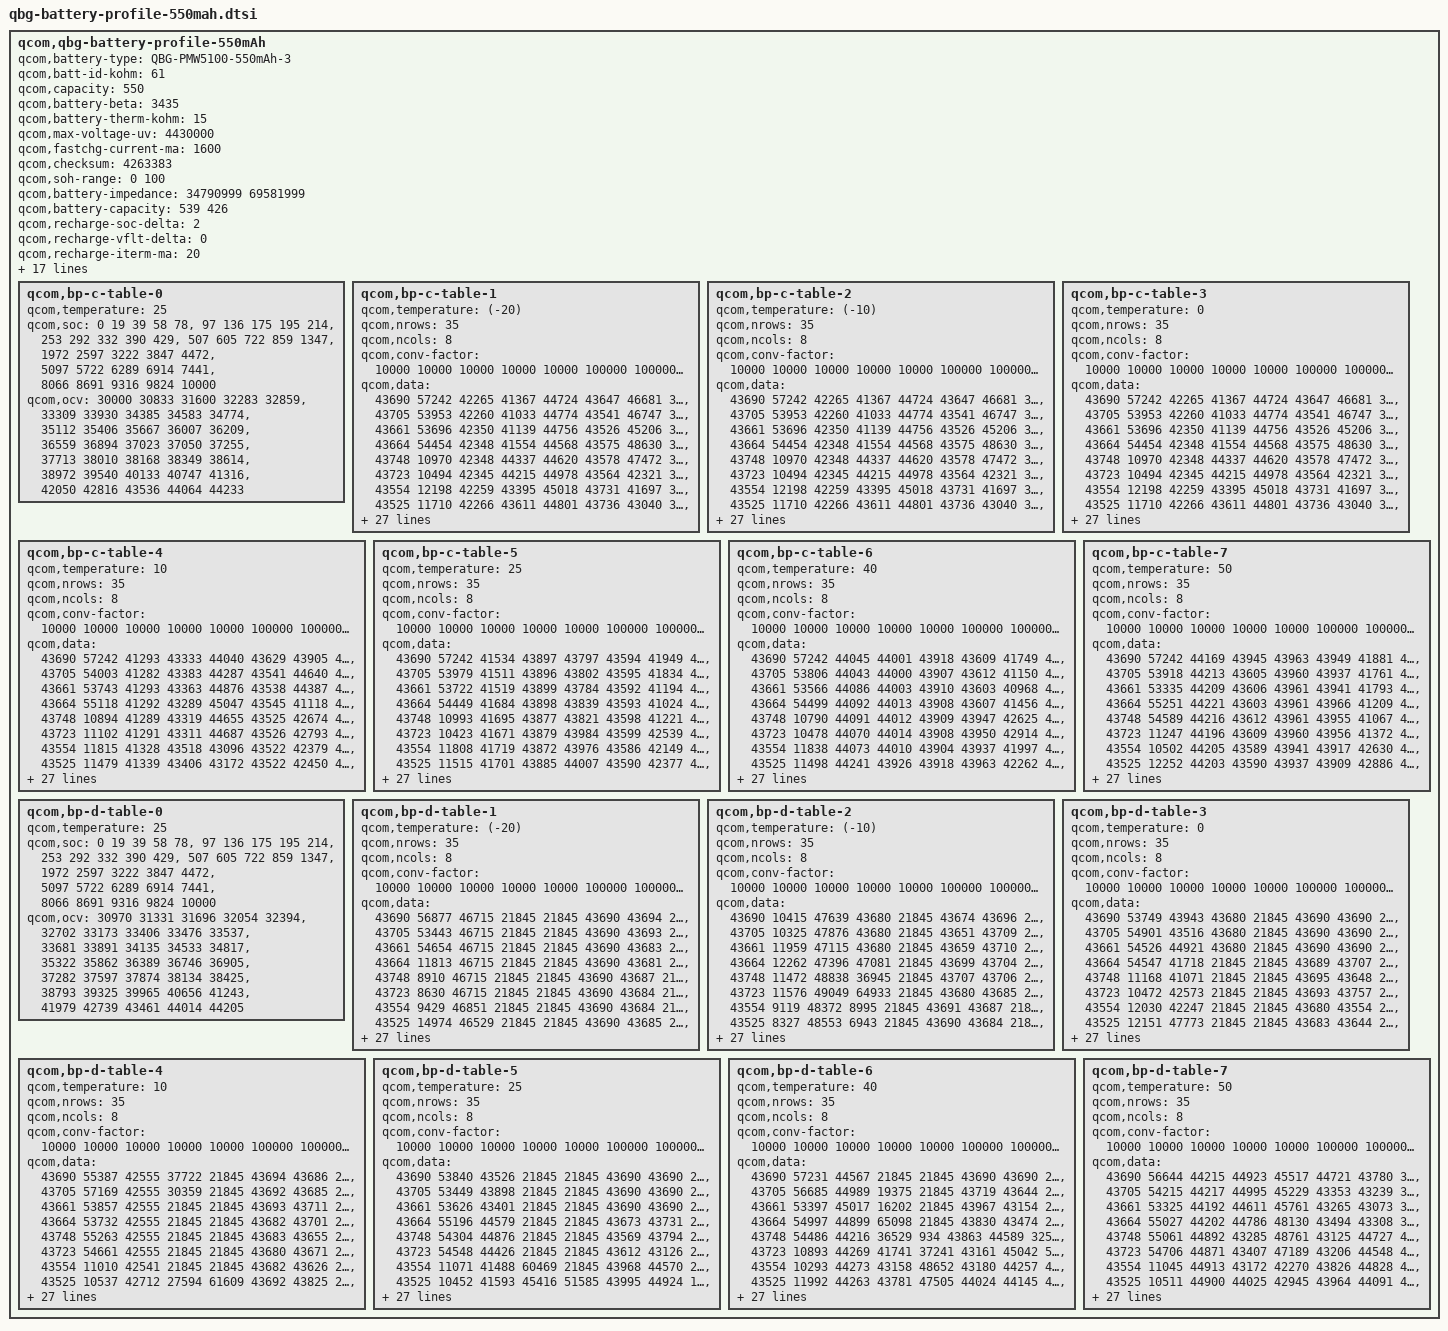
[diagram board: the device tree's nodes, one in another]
qcom,qbg-battery-profile-550mAh {
	qcom,battery-type = "QBG-PMW5100-550mAh-3";
	qcom,batt-id-kohm = <61>;
	qcom,capacity = <550>;
	qcom,battery-beta = <3435>;
	qcom,battery-therm-kohm = <15>;
	qcom,max-voltage-uv = <4430000>;
	qcom,fastchg-current-ma = <1600>;
	qcom,checksum = <4263383>; /*@5, 0.005V, 6.0% */
	qcom,soh-range = <0 100>;
	/* Nominal_Impedance in 10nohm @ SOC 50% 25C* 0:fresh cell,  1: aged cell */
	qcom,battery-impedance = <34790999 69581999>;
	/* Nominal_Capacity in mAh. 0: fresh cell,  1:aged cell */
	qcom,battery-capacity = <539 426>;
	/* SOC delta (in percent) dropped from EOC SOC to enable recharge */
	qcom,recharge-soc-delta =<2>;
	/* vfloat delta (in mV) dropped from regular vfloat in recharge */
	qcom,recharge-vflt-delta =<0>;
	/* Termination current (in mA) in recharge */
	qcom,recharge-iterm-ma = <20>;
	qcom,batt-temp-coeffs =    <0 70 120 170 425 440 530>;
	qcom,batt-current-coeffs = <0 250000 525000 800000 1600000 650000 300000>;
	qcom,batt-max-mv-coeffs = <4130000 4430000>;
	qcom,chg-limit-current-default = <150000>;

	qcom,jeita-fcc-ranges = <0  70  250000
                            	71 440 1600000
                            	441 530 300000>;

   	 qcom,jeita-fv-ranges = <0  70  4430000
                           	71  440 4430000
                           	441 530 4130000>;

	qcom,step-chg-ranges = <3400000  4250000  1600000
				4250001  4350000  1250000
				4350001  4430000  1100000>;
    	/* COOL = 15 DegC, WARM = 70 DegC */
    	qcom,jeita-soft-thresholds = <0x30DD 0x7BC>;
    	/* COLD = 0 DegC, HOT = 80 DegC */
    	qcom,jeita-hard-thresholds = <0x3733 0x5ed>;
   	/* COOL = 18 DegC, WARM = 39 DegC*/
    	qcom,jeita-soft-hys-thresholds = <0x256e 0x161b>;
    	qcom,jeita-soft-fcc-ua = <250000 650000>;
    	qcom,jeita-soft-fv-uv = <4430000 4430000>;

	qcom,bp-c-table-0 {
		qcom,temperature = <25>;
		qcom,soc = <    0    19    39    58    78>,
			<   97   136   175   195   214>,
			<  253   292   332   390   429>,
			<  507   605   722   859  1347>,
			< 1972  2597  3222  3847  4472>,
			< 5097  5722  6289  6914  7441>,
			< 8066  8691  9316  9824 10000>;
		qcom,ocv = <30000 30833 31600 32283 32859>,
			<33309 33930 34385 34583 34774>,
			<35112 35406 35667 36007 36209>,
			<36559 36894 37023 37050 37255>,
			<37713 38010 38168 38349 38614>,
			<38972 39540 40133 40747 41316>,
			<42050 42816 43536 44064 44233>;
	};

	qcom,bp-c-table-1 {
		qcom,temperature = <(-20)>;
		qcom,nrows = <35>;
		qcom,ncols = <8>;
		qcom,conv-factor = <10000 10000 10000 10000 10000 100000 100000 10000>;
		qcom,data = <43690 57242 42265 41367 44724 43647 46681 39662>,
			    <43705 53953 42260 41033 44774 43541 46747 34189>,
			    <43661 53696 42350 41139 44756 43526 45206 34681>,
			    <43664 54454 42348 41554 44568 43575 48630 34557>,
			    <43748 10970 42348 44337 44620 43578 47472 32879>,
			    <43723 10494 42345 44215 44978 43564 42321 33671>,
			    <43554 12198 42259 43395 45018 43731 41697 35968>,
			    <43525 11710 42266 43611 44801 43736 43040 35192>,
			    <43625 11590 42244 43765 44819 43739 43964 35236>,
			    <43644  8731 42247 43754 44816 43736 43646 34869>,
			    <43607  8361 42252 43677 44808 43735 43647 35001>,
			    <43918  8628 42292 43672 44844 43559 43645 35612>,
			    <44006  9911 42291 43674 44841 43577 43639 35780>,
			    <43820 10176 42282 43672 44847 43582 43591 35767>,
			    <43783  9370 42462 43673 44846 43582 43611 35400>,
			    <43857  9507 42465 43675 44998 43571 43609 35531>,
			    <43255 14852 42396 43692 44948 43073 43594 46348>,
			    <43128 14929 42393 43748 45028 43581 43613 46534>,
			    <43505 15283 42392 43235 43289 43535 45030 46363>,
			    <45033 15191 42413 44648 43325 43540 41374 35436>,
			    <44318 14666 42082 44982 45042 43616 41414 35824>,
			    <41103 16310 41998 45012 44281 43623 41333 35589>,
			    <42556 16178 42043 44806 44091 43617 42660 35620>,
			    <42413 15505 42025 44916 44254 43628 41312 35729>,
			    <48082 15795 42030 44169 44285 43625 40979 35752>,
			    <47427 13026 42138 44918 44435 43627 44394 35821>,
			    <48368 13174 42165 44269 44374 43626 42807 35002>,
			    <45627 13873 42161 44820 44619 43543 41661 46218>,
			    <45480 13412 42145 44871 44636 43543 41150 46329>,
			    <47035  2643 42823 44876 44575 43536 41635 46252>,
			    <46376  2308 42847 44168 44939 43537 44334 46507>,
			    <35673  3129 42823 44061 44171 43548 44128 35817>,
			    <36558   991 42211 44244 41083 43630 44604 33291>,
			    <36042   262 42108 43439 42075 43253 43860 34711>,
			    <36282  1767 42443 43898 42551 43535 44018 33279>;
	};

	qcom,bp-c-table-2 {
		qcom,temperature = <(-10)>;
		qcom,nrows = <35>;
		qcom,ncols = <8>;
		qcom,conv-factor = <10000 10000 10000 10000 10000 100000 100000 10000>;
		qcom,data = <43690 57242 42265 41367 44724 43647 46681 39662>,
			    <43705 53953 42260 41033 44774 43541 46747 34189>,
			    <43661 53696 42350 41139 44756 43526 45206 34681>,
			    <43664 54454 42348 41554 44568 43575 48630 34557>,
			    <43748 10970 42348 44337 44620 43578 47472 32879>,
			    <43723 10494 42345 44215 44978 43564 42321 33671>,
			    <43554 12198 42259 43395 45018 43731 41697 35968>,
			    <43525 11710 42266 43611 44801 43736 43040 35192>,
			    <43625 11590 42244 43765 44819 43739 43964 35236>,
			    <43644  8731 42247 43754 44816 43736 43646 34869>,
			    <43607  8361 42252 43677 44808 43735 43647 35001>,
			    <43918  8628 42292 43672 44844 43559 43645 35612>,
			    <44006  9911 42291 43674 44841 43577 43639 35780>,
			    <43820 10176 42282 43672 44847 43582 43591 35767>,
			    <43783  9370 42462 43673 44846 43582 43611 35400>,
			    <43857  9507 42465 43675 44998 43571 43609 35531>,
			    <43255 14852 42396 43692 44948 43073 43594 46348>,
			    <43128 14929 42393 43748 45028 43581 43613 46534>,
			    <43505 15283 42392 43235 43289 43535 45030 46363>,
			    <45033 15191 42413 44648 43325 43540 41374 35436>,
			    <44318 14666 42082 44982 45042 43616 41414 35824>,
			    <41103 16310 41998 45012 44281 43623 41333 35589>,
			    <42556 16178 42043 44806 44091 43617 42660 35620>,
			    <42413 15505 42025 44916 44254 43628 41312 35729>,
			    <48082 15795 42030 44169 44285 43625 40979 35752>,
			    <47427 13026 42138 44918 44435 43627 44394 35821>,
			    <48368 13174 42165 44269 44374 43626 42807 35002>,
			    <45627 13873 42161 44820 44619 43543 41661 46218>,
			    <45480 13412 42145 44871 44636 43543 41150 46329>,
			    <47035  2643 42823 44876 44575 43536 41635 46252>,
			    <46376  2308 42847 44168 44939 43537 44334 46507>,
			    <35673  3129 42823 44061 44171 43548 44128 35817>,
			    <36558   991 42211 44244 41083 43630 44604 33291>,
			    <36042   262 42108 43439 42075 43253 43860 34711>,
			    <36282  1767 42443 43898 42551 43535 44018 33279>;
	};

	qcom,bp-c-table-3 {
		qcom,temperature = <0>;
		qcom,nrows = <35>;
		qcom,ncols = <8>;
		qcom,conv-factor = <10000 10000 10000 10000 10000 100000 100000 10000>;
		qcom,data = <43690 57242 42265 41367 44724 43647 46681 39662>,
			    <43705 53953 42260 41033 44774 43541 46747 34189>,
			    <43661 53696 42350 41139 44756 43526 45206 34681>,
			    <43664 54454 42348 41554 44568 43575 48630 34557>,
			    <43748 10970 42348 44337 44620 43578 47472 32879>,
			    <43723 10494 42345 44215 44978 43564 42321 33671>,
			    <43554 12198 42259 43395 45018 43731 41697 35968>,
			    <43525 11710 42266 43611 44801 43736 43040 35192>,
			    <43625 11590 42244 43765 44819 43739 43964 35236>,
			    <43644  8731 42247 43754 44816 43736 43646 34869>,
			    <43607  8361 42252 43677 44808 43735 43647 35001>,
			    <43918  8628 42292 43672 44844 43559 43645 35612>,
			    <44006  9911 42291 43674 44841 43577 43639 35780>,
			    <43820 10176 42282 43672 44847 43582 43591 35767>,
			    <43783  9370 42462 43673 44846 43582 43611 35400>,
			    <43857  9507 42465 43675 44998 43571 43609 35531>,
			    <43255 14852 42396 43692 44948 43073 43594 46348>,
			    <43128 14929 42393 43748 45028 43581 43613 46534>,
			    <43505 15283 42392 43235 43289 43535 45030 46363>,
			    <45033 15191 42413 44648 43325 43540 41374 35436>,
			    <44318 14666 42082 44982 45042 43616 41414 35824>,
			    <41103 16310 41998 45012 44281 43623 41333 35589>,
			    <42556 16178 42043 44806 44091 43617 42660 35620>,
			    <42413 15505 42025 44916 44254 43628 41312 35729>,
			    <48082 15795 42030 44169 44285 43625 40979 35752>,
			    <47427 13026 42138 44918 44435 43627 44394 35821>,
			    <48368 13174 42165 44269 44374 43626 42807 35002>,
			    <45627 13873 42161 44820 44619 43543 41661 46218>,
			    <45480 13412 42145 44871 44636 43543 41150 46329>,
			    <47035  2643 42823 44876 44575 43536 41635 46252>,
			    <46376  2308 42847 44168 44939 43537 44334 46507>,
			    <35673  3129 42823 44061 44171 43548 44128 35817>,
			    <36558   991 42211 44244 41083 43630 44604 33291>,
			    <36042   262 42108 43439 42075 43253 43860 34711>,
			    <36282  1767 42443 43898 42551 43535 44018 33279>;
	};

	qcom,bp-c-table-4 {
		qcom,temperature = <10>;
		qcom,nrows = <35>;
		qcom,ncols = <8>;
		qcom,conv-factor = <10000 10000 10000 10000 10000 100000 100000 10000>;
		qcom,data = <43690 57242 41293 43333 44040 43629 43905 46094>,
			    <43705 54003 41282 43383 44287 43541 44640 46971>,
			    <43661 53743 41293 43363 44876 43538 44387 46656>,
			    <43664 55118 41292 43289 45047 43545 41118 45395>,
			    <43748 10894 41289 43319 44655 43525 42674 45481>,
			    <43723 11102 41291 43311 44687 43526 42793 45242>,
			    <43554 11815 41328 43518 43096 43522 42379 45798>,
			    <43525 11479 41339 43406 43172 43522 42450 48207>,
			    <43625 11768 41319 43431 43877 43522 42464 48335>,
			    <43644  8883 41314 43100 43807 43523 42006 48291>,
			    <43607  9170 41238 43030 43835 43546 41443 49116>,
			    <43918  8206 41220 43065 43990 43539 41610 49082>,
			    <44006  8455 41268 43045 43995 43541 44370 48760>,
			    <43820 10155 41256 43045 43970 43631 41727 48700>,
			    <43783 10080 41415 43040 43969 43618 41701 48860>,
			    <43857  9614 41440 43225 43818 43617 44329 48789>,
			    <43255 15092 41423 43231 43983 43617 41580 47448>,
			    <43128 14873 41414 43047 44004 43622 41199 47388>,
			    <43505 14969 41441 43061 43996 43622 41018 47381>,
			    <45033 15108 41449 43094 43113 43638 41090 48741>,
			    <44318 14636 41386 43496 44715 43587 41397 48945>,
			    <41103 15894 41039 43314 44640 43599 41245 48275>,
			    <42556 16277 41087 43288 44608 43596 42656 48311>,
			    <42413 16196 40982 43388 44557 43594 41221 48925>,
			    <48082 15433 40973 44705 44753 43635 41203 48940>,
			    <47427 12956 40999 44700 44646 43646 44303 48997>,
			    <48368 12435 41154 43269 44855 43645 44114 49011>,
			    <45627 13938 41197 43312 43447 43600 44292 47522>,
			    <45480 13747 41114 43370 43408 43601 44364 47519>,
			    <47035  3048 41095 43390 43508 43641 44309 47604>,
			    <46376  3770 41141 43331 43286 43641 44145 47445>,
			    <35673  3499 41103 44684 44776 43645 44147 49077>,
			    <36558   886 41205 44775 44151 43644 45010 45692>,
			    <36042   320 41387 43474 41893 43591 43515 45433>,
			    <36282  1598 41422 43104 41658 43941 43237 45465>;
	};

	qcom,bp-c-table-5 {
		qcom,temperature = <25>;
		qcom,nrows = <35>;
		qcom,ncols = <8>;
		qcom,conv-factor = <10000 10000 10000 10000 10000 100000 100000 10000>;
		qcom,data = <43690 57242 41534 43897 43797 43594 41949 42819>,
			    <43705 53979 41511 43896 43802 43595 41834 42863>,
			    <43661 53722 41519 43899 43784 43592 41194 42760>,
			    <43664 54449 41684 43898 43839 43593 41024 42794>,
			    <43748 10993 41695 43877 43821 43598 41221 42997>,
			    <43723 10423 41671 43879 43984 43599 42539 42901>,
			    <43554 11808 41719 43872 43976 43586 42149 42921>,
			    <43525 11515 41701 43885 44007 43590 42377 42597>,
			    <43625 11709 41699 43884 44014 43588 42480 42514>,
			    <43644 11644 41705 43887 43921 43589 42484 42505>,
			    <43607  9090 41628 43880 43907 43614 42489 42706>,
			    <43918  8420 41607 43882 43957 43602 42476 42742>,
			    <44006  8697 41603 43796 43912 43606 42493 42750>,
			    <43820  9741 41615 43792 43910 43946 42299 42727>,
			    <43783 10203 41608 43795 43908 43947 42298 42729>,
			    <43857  9317 41660 43800 43930 43945 42445 42636>,
			    <43255 15028 41642 43838 43910 43948 42964 41281>,
			    <43128 14901 44369 43981 43959 43936 42536 41269>,
			    <43505 14864 44359 43985 44026 43937 42497 41343>,
			    <45033 15149 44415 43803 43235 43937 41522 42616>,
			    <44318 14843 44311 43902 43093 43915 41124 42963>,
			    <41103 16080 44296 43860 43505 43966 41344 42865>,
			    <42556 16306 44329 43180 43453 43936 41272 42968>,
			    <42413 16231 44486 43166 43078 43950 40962 42995>,
			    <48082 15484 44513 43257 43081 43602 41614 42977>,
			    <47427 12950 44420 43205 43498 43606 44228 42761>,
			    <48368 12510 44451 43191 43097 43604 44124 42574>,
			    <45627 13935 44102 43891 43864 43609 44501 41410>,
			    <45480 13697 44159 43876 43858 43609 44232 41441>,
			    <47035  3022 44139 43857 43196 43610 44114 41256>,
			    <46376  3816 44057 43193 43213 43589 44254 41294>,
			    <35673  3562 44061 43140 43125 43615 44216 42531>,
			    <36558   186 44135 43070 43385 43950 44202 42169>,
			    <36042  1674 44520 43864 44234 43609 43331 47829>,
			    <36282  1635 44404 44029 44660 43911 43231 42416>;
	};

	qcom,bp-c-table-6 {
		qcom,temperature = <40>;
		qcom,nrows = <35>;
		qcom,ncols = <8>;
		qcom,conv-factor = <10000 10000 10000 10000 10000 100000 100000 10000>;
		qcom,data =<43690 57242 44045 44001 43918 43609 41749 41752>,
			    <43705 53806 44043 44000 43907 43612 41150 41729>,
			    <43661 53566 44086 44003 43910 43603 40968 41742>,
			    <43664 54499 44092 44013 43908 43607 41456 41783>,
			    <43748 10790 44091 44012 43909 43947 42625 41790>,
			    <43723 10478 44070 44014 43908 43950 42914 41766>,
			    <43554 11838 44073 44010 43904 43937 41997 41939>,
			    <43525 11498 44241 43926 43918 43963 42262 41934>,
			    <43625 11348 44253 43920 43914 43960 42311 41971>,
			    <43644 11548 44254 43933 43953 43961 42307 41959>,
			    <43607  8788 44229 43931 43942 43966 42351 41882>,
			    <43918  8375 44224 43911 43947 43964 42243 41904>,
			    <44006  8631 44239 43904 43605 43955 42253 41893>,
			    <43820  9926 44276 43917 43607 43912 42252 41902>,
			    <43783 10136 44273 43916 43601 43916 42244 41559>,
			    <43857  9251 44287 43919 43613 43911 42365 41541>,
			    <43255  9595 44283 43955 43610 43935 42392 41594>,
			    <43128 15050 44259 43595 43637 44027 42590 41685>,
			    <43505 15057 44271 43591 43945 44007 41049 41476>,
			    <45033 15259 44183 43909 43991 44015 41186 41934>,
			    <44318 14426 44186 43935 43889 44001 41068 41747>,
			    <41103 16050 44174 43930 43171 44015 41104 41842>,
			    <42556 15990 44196 43911 43780 43928 41450 41935>,
			    <42413 16128 44880 44012 43791 43956 41587 41923>,
			    <48082 15469 44872 44020 43902 43952 44156 41743>,
			    <47427 13036 44900 43984 43172 43965 44866 41792>,
			    <48368 12336 44818 43911 43829 43908 44231 41915>,
			    <45627 13949 44809 43961 43961 43909 41506 41696>,
			    <45480 13806 44839 43954 43911 43907 44318 41727>,
			    <47035  2860 45014 43927 44029 43912 41519 41522>,
			    <46376  3779 45018 44006 43784 43913 44304 41549>,
			    <35673  3530 45004 43969 43869 43959 44350 41981>,
			    <36558   143 44992 43810 43258 43955 44330 41849>,
			    <36042  1665 44813 44022 44776 43919 45046 41341>,
			    <36282  1651 44271 43914 43466 44030 43322 41469>;
	};

	qcom,bp-c-table-7 {
		qcom,temperature = <50>;
		qcom,nrows = <35>;
		qcom,ncols = <8>;
		qcom,conv-factor = <10000 10000 10000 10000 10000 100000 100000 10000>;
		qcom,data = <43690 57242 44169 43945 43963 43949 41881 41492>,
			    <43705 53918 44213 43605 43960 43937 41761 41503>,
			    <43661 53335 44209 43606 43961 43941 41793 41478>,
			    <43664 55251 44221 43603 43961 43966 41209 41481>,
			    <43748 54589 44216 43612 43961 43955 41067 41520>,
			    <43723 11247 44196 43609 43960 43956 41372 41528>,
			    <43554 10502 44205 43589 43941 43917 42630 41515>,
			    <43525 12252 44203 43590 43937 43909 42886 41688>,
			    <43625 11498 44884 43585 43939 43931 42756 41665>,
			    <43644 11349 44886 43585 43948 43928 42135 41678>,
			    <43607  8955 44882 43584 43605 43934 42284 41714>,
			    <43918  9181 44894 43585 43602 43935 47824 41697>,
			    <44006  8404 44891 43584 43611 43933 48043 41621>,
			    <43820  8572 44870 43586 43586 43926 47929 41604>,
			    <43783  9739 44864 43597 43598 43925 47879 41615>,
			    <43857  9384 44877 43598 43639 44015 47968 41663>,
			    <43255  9718 44875 43637 43641 44005 47286 41642>,
			    <43128 15031 44916 43548 43547 43820 42328 44289>,
			    <43505 14993 44918 43549 43616 43987 41265 44393>,
			    <45033 14960 44914 43945 43905 43982 42767 41688>,
			    <44318 14388 44901 43615 44024 43999 42686 41518>,
			    <41103 14719 44911 43592 43996 43992 41124 41530>,
			    <42556 15893 44818 43637 43910 43976 41362 41628>,
			    <42413 16180 44800 43939 43930 44004 41022 41712>,
			    <48082 15458 44850 43907 44016 44014 41519 41481>,
			    <47427 13048 44834 44009 43985 43934 44324 41592>,
			    <48368 12293 45019 43607 43959 44005 41595 41637>,
			    <45627 13895 45002 43646 43621 44028 41010 44499>,
			    <45480 13813 45028 43633 43608 44019 41972 44345>,
			    <47035  2818 44945 43587 43915 44024 41570 44395>,
			    <46376  3619 44931 43942 44023 44013 41765 41656>,
			    <35673  3543 44982 43954 43786 44010 41520 41724>,
			    <36558   153 44989 43926 43892 44015 41858 41502>,
			    <36042  1692 44949 43938 43453 44014 44908 41803>,
			    <36282  1610 44918 43930 43256 43814 44947 41805>;
	};

	qcom,bp-d-table-0 {
		qcom,temperature = <25>;
		qcom,soc = <    0    19    39    58    78>,
			<   97   136   175   195   214>,
			<  253   292   332   390   429>,
			<  507   605   722   859  1347>,
			< 1972  2597  3222  3847  4472>,
			< 5097  5722  6289  6914  7441>,
			< 8066  8691  9316  9824 10000>;
		qcom,ocv = <30970 31331 31696 32054 32394>,
			<32702 33173 33406 33476 33537>,
			<33681 33891 34135 34533 34817>,
			<35322 35862 36389 36746 36905>,
			<37282 37597 37874 38134 38425>,
			<38793 39325 39965 40656 41243>,
			<41979 42739 43461 44014 44205>;
	};

	qcom,bp-d-table-1 {
		qcom,temperature = <(-20)>;
		qcom,nrows = <35>;
		qcom,ncols = <8>;
		qcom,conv-factor = <10000 10000 10000 10000 10000 100000 100000 10000>;
		qcom,data = <43690 56877 46715 21845 21845 43690 43694 21845>,
			    <43705 53443 46715 21845 21845 43690 43693 21845>,
			    <43661 54654 46715 21845 21845 43690 43683 21845>,
			    <43664 11813 46715 21845 21845 43690 43681 21845>,
			    <43748  8910 46715 21845 21845 43690 43687 21845>,
			    <43723  8630 46715 21845 21845 43690 43684 21845>,
			    <43554  9429 46851 21845 21845 43690 43684 21845>,
			    <43525 14974 46529 21845 21845 43690 43685 21845>,
			    <43625 15345 35499 21845 21845 43690 43685 21845>,
			    <43644 15353 35469 21845 21845 43690 43685 21845>,
			    <43607  9555 35563 21845 21845 43690 43687 21845>,
			    <43918  9253 35567 21845 21845 43690 43687 21845>,
			    <44006  9217 35481 21845 21845 43690 43687 21845>,
			    <43820  9587 46421 21845 21845 43690 43704 21845>,
			    <43783  9584 35467 21845 21845 43691 43729 21845>,
			    <43857  9280 35814 21845 35524 43692 43310 21845>,
			    <43255  9666 46591 21845 46116 43692 43426 21845>,
			    <43128  9582 35457 21845 48573 43692 43275 21845>,
			    <43505  9557 46305 24215 47344 43693 43315 21845>,
			    <45033 14849 46875 16201 42248 43689 43863 21845>,
			    <44318 15204 46917 50923 42126 43688 43259 21686>,
			    <41103 14448 47057 63694 42816 43688 43202 30014>,
			    <42556 14619 47058 38092 42995 43688 43234 27745>,
			    <42413 16068 47051 39588 42509 43688 43246  8163>,
			    <48082 16264 46881 36547 42688 43689 43183  3946>,
			    <47427 16215 47066 46772 42719 43689 43847 12483>,
			    <48368 15836 46870 45795 42771 43694 43061 16073>,
			    <45627 13178 46875 45972 47536 43694 44747 15640>,
			    <45480 14328 46864 46738 46554 43693 44515  3713>,
			    <47035  2801 46675 45246 34706 43683 44548  2023>,
			    <46376  2209 46865 45815 35407 43711 43027  2675>,
			    <35673  3901 46927 46045 46348 43771 44544  3182>,
			    <36558   557 46849 46877 46942 43702 43459  3184>,
			    <36042   310 46874 35786 48403 43690 43567  2196>,
			    <36282  1623 46950 35779 48380 43690 43690 13601>;
	};

	qcom,bp-d-table-2 {
		qcom,temperature = <(-10)>;
		qcom,nrows = <35>;
		qcom,ncols = <8>;
		qcom,conv-factor = <10000 10000 10000 10000 10000 100000 100000 10000>;
		qcom,data = <43690 10415 47639 43680 21845 43674 43696 21845>,
			    <43705 10325 47876 43680 21845 43651 43709 21845>,
			    <43661 11959 47115 43680 21845 43659 43710 21845>,
			    <43664 12262 47396 47081 21845 43699 43704 21845>,
			    <43748 11472 48838 36945 21845 43707 43706 21845>,
			    <43723 11576 49049 64933 21845 43680 43685 21845>,
			    <43554  9119 48372  8995 21845 43691 43687 21845>,
			    <43525  8327 48553  6943 21845 43690 43684 21845>,
			    <43625  8312 48615 27484 21845 43690 43685 21845>,
			    <43644  8670 48417 30874 21845 43690 43707 21845>,
			    <43607  9872 48490 20557 21845 43690 43696 21845>,
			    <43918  9926 48421 21845 21845 43689 44010 21845>,
			    <44006  9765 48620 21845 59167 43693 43092 21845>,
			    <43820 10217 48551 21845 45643 43682 44707 21845>,
			    <43783  9380 48204 21845 48364 43682 44747 21845>,
			    <43857  9235 48190 25294 47908 43692 43359 21845>,
			    <43255  9633 48335 13728 42042 43689 43014 21845>,
			    <43128  9702 48294 53336 42646 43688 43201 23062>,
			    <43505  9507 48972 62784 41015 43688 43214 31212>,
			    <45033 14891 49013 37793 41834 43688 43065  2346>,
			    <44318 14526 49111 35502 40967 43689 43123 10559>,
			    <41103 14734 49004 47335 41060 43694 43025 50250>,
			    <42556 14717 48920 41224 41566 43692 43059 62715>,
			    <42413 16088 48953 41966 44351 43680 43047 63564>,
			    <48082 16257 48974 44416 44452 43696 43226 57822>,
			    <47427 15365 49102 41612 44289 43567 44512 58197>,
			    <48368 12913 49092 41500 42794 43576 44043 59304>,
			    <45627 12790 49117 41390 47505 43527 44476 63806>,
			    <45480 13423 49091 41030 35330 43521 44737 62941>,
			    <47035  2769 49115 42499 48183 43581 43406 64970>,
			    <46376  2519 49054 42865 49018 43578 44604 62457>,
			    <35673  3293 48727 42878 48362 43557 44975 61746>,
			    <36558  1022 49049 42918 48780 43553 44550 61776>,
			    <36042   325 48941 42605 42870 43734 44607 62227>,
			    <36282  1625 48951 42606 42622 43730 44593 62140>;
	};

	qcom,bp-d-table-3 {
		qcom,temperature = <0>;
		qcom,nrows = <35>;
		qcom,ncols = <8>;
		qcom,conv-factor = <10000 10000 10000 10000 10000 100000 100000 10000>;
		qcom,data = <43690 53749 43943 43680 21845 43690 43690 21845>,
			    <43705 54901 43516 43680 21845 43690 43690 21845>,
			    <43661 54526 44921 43680 21845 43690 43690 21845>,
			    <43664 54547 41718 21845 21845 43689 43707 21845>,
			    <43748 11168 41071 21845 21845 43695 43648 21845>,
			    <43723 10472 42573 21845 21845 43693 43757 21845>,
			    <43554 12030 42247 21845 21845 43680 43554 21845>,
			    <43525 12151 47773 21845 21845 43683 43644 21845>,
			    <43625 11306 47859 21845 25754 43683 43945 21845>,
			    <43644 11711 47835 21845  9390 43682 43935 21845>,
			    <43607  8833 47831 21845 59052 43693 43777 21845>,
			    <43918  9094 47851 22366 33146 43692 43204 21845>,
			    <44006  8371 42329  4798 45825 43694 43406 21845>,
			    <43820  8654 42351 54440 47499 43689 43463 20423>,
			    <43783  9860 42271 53153 48102 43688 43304 31436>,
			    <43857 10040 42346 59715 42301 43688 43379  1789>,
			    <43255  9230 42299 34013 42959 43688 43365  9292>,
			    <43128  9624 42271 46347 41385 43689 43432 53821>,
			    <43505  9685 42267 48293 41885 43689 43086 49801>,
			    <45033 15074 42303 41010 44416 43693 43423 58898>,
			    <44318 14495 42447 44108 44531 43651 44261 38478>,
			    <41103 14835 42481 45031 44102 43581 44151 39800>,
			    <42556 14711 42395 44789 44762 43534 44855 33763>,
			    <42413 16087 42428 44764 43373 43525 44353 36644>,
			    <48082 16131 42414 44559 45012 43547 44328 36737>,
			    <47427 15771 42401 44659 44145 43551 44152 36802>,
			    <48368 13303 42057 44832 41090 43626 44060 33524>,
			    <45627 14000 42008 44268 47352 43629 44997 39855>,
			    <45480 13438 42003 44392 47723 43536 43497 39526>,
			    <47035  2990 42011 41634 42597 43522 43346 34612>,
			    <46376  2376 42014 44366 41335 43535 44638 34755>,
			    <35673  3188 41985 44339 42599 43521 44951 34088>,
			    <36558   769 41991 44466 42726 43547 44935 39657>,
			    <36042  1705 42176 44235 41555 43546 44625 34587>,
			    <36282  1614 42214 44168 44413 43524 44621 33079>;
	};

	qcom,bp-d-table-4 {
		qcom,temperature = <10>;
		qcom,nrows = <35>;
		qcom,ncols = <8>;
		qcom,conv-factor = <10000 10000 10000 10000 10000 100000 100000 10000>;
		qcom,data = <43690 55387 42555 37722 21845 43694 43686 21845>,
			    <43705 57169 42555 30359 21845 43692 43685 21845>,
			    <43661 53857 42555 21845 21845 43693 43711 21845>,
			    <43664 53732 42555 21845 21845 43682 43701 21845>,
			    <43748 55263 42555 21845 21845 43683 43655 21845>,
			    <43723 54661 42555 21845 21845 43680 43671 21845>,
			    <43554 11010 42541 21845 21845 43682 43626 21845>,
			    <43525 10537 42712 27594 61609 43692 43825 21845>,
			    <43625 12029 42691 54082 33805 43695 43841 17828>,
			    <43644 12169 42699 62465 35844 43695 43198 25346>,
			    <43607 11322 42727 37411 46321 43694 43238 12386>,
			    <43918 11640 42642 35242 46035 43694 43048 54336>,
			    <44006  8799 42634 46037 49142 43695 43128 49551>,
			    <43820  8412 41301 48118 48040 43683 43508 64949>,
			    <43783  8695 41309 42845 42418 43684 43270 59243>,
			    <43857  9818 41298 41845 42564 43703 44733 60336>,
			    <43255  9430 42678 44367 42693 43653 44690 37792>,
			    <43128  9718 41299 44039 41028 43754 44607 39130>,
			    <43505  9476 41328 44959 44322 43751 44552 33610>,
			    <45033 15100 41326 44708 44802 43736 44907 35791>,
			    <44318 14521 41249 43497 44680 43522 44249 45248>,
			    <41103 14745 41448 43455 43284 43617 41604 48437>,
			    <42556 14709 41354 43127 43463 43643 41639 48304>,
			    <42413 15983 41040 43091 44707 43644 44352 49014>,
			    <48082 16219 41033 43446 44724 43644 44306 49150>,
			    <47427 15812 40986 43420 44797 43645 44527 49051>,
			    <48368 13067 40975 43286 44338 43633 44055 45583>,
			    <45627 13980 41021 44799 41434 43638 44737 47006>,
			    <45480 13426 41011 44653 41510 43631 43326 45159>,
			    <47035  2999 41009 44597 44051 43551 43329 45984>,
			    <46376  3754 41016 44579 44208 43551 44669 45694>,
			    <35673  3157 40972 44767 44247 43541 45010 45951>,
			    <36558   867 41073 44677 44053 43618 44848 45163>,
			    <36042  1710 41388 44729 44906 43642 44252 45085>,
			    <36282  1658 41400 44730 44973 43641 44050 45252>;
	};

	qcom,bp-d-table-5 {
		qcom,temperature = <25>;
		qcom,nrows = <35>;
		qcom,ncols = <8>;
		qcom,conv-factor = <10000 10000 10000 10000 10000 100000 100000 10000>;
		qcom,data = <43690 53840 43526 21845 21845 43690 43690 21845>,
			    <43705 53449 43898 21845 21845 43690 43690 21845>,
			    <43661 53626 43401 21845 21845 43690 43690 21845>,
			    <43664 55196 44579 21845 21845 43673 43731 21845>,
			    <43748 54304 44876 21845 21845 43569 43794 21845>,
			    <43723 54548 44426 21845 21845 43612 43126 21845>,
			    <43554 11071 41488 60469 21845 43968 44570 21845>,
			    <43525 10452 41593 45416 51585 43995 44924 15570>,
			    <43625 10350 41494 47599 63762 43981 44263 54129>,
			    <43644 10667 41481 42920 57889 44016 44059 53126>,
			    <43607 10555 41684 44119 40345 43924 44429 57477>,
			    <43918 11977 41671 45028 35905 43955 44534 40347>,
			    <44006 12285 41675 44787 45058 43615 44502 32992>,
			    <43820 11343 41700 43312 48065 43636 44502 35471>,
			    <43783  8875 41621 43494 42859 43644 44505 46761>,
			    <43857  9040 41624 43074 41936 43646 44505 48553>,
			    <43255  9916 41612 43065 44136 43621 44510 47360>,
			    <43128  9359 41649 43213 44671 43641 44535 48097>,
			    <43505  9504 44373 43249 44852 43597 44993 47987>,
			    <45033 14979 44407 43786 43234 43588 44279 42984>,
			    <44318 15112 44317 43818 43195 43947 44466 42711>,
			    <41103 14455 44325 43995 43188 43947 44331 42654>,
			    <42556 14680 44508 43786 43481 43936 44487 42970>,
			    <42413 15964 44512 43805 43501 43943 44458 42891>,
			    <48082 15539 44428 43882 43037 43605 44524 42703>,
			    <47427 15651 44476 43874 43051 43601 44528 42673>,
			    <48368 13111 44113 43192 44711 43603 44220 42869>,
			    <45627 14007 44098 43039 45052 43615 44629 42343>,
			    <45480 13434 44151 43206 44683 43634 43286 42212>,
			    <47035  2993 44155 43258 43454 43645 44693 42935>,
			    <46376  2385 44134 43159 43057 43620 44971 42537>,
			    <35673  3161 44132 43870 43065 43634 44571 42729>,
			    <36558   879 44106 43175 43059 43637 44164 42539>,
			    <36042   324 44110 43782 43081 43590 44195 42536>,
			    <36282  1543 44105 43969 43093 43611 44816 42718>;
	};

	qcom,bp-d-table-6 {
		qcom,temperature = <40>;
		qcom,nrows = <35>;
		qcom,ncols = <8>;
		qcom,conv-factor = <10000 10000 10000 10000 10000 100000 100000 10000>;
		qcom,data = <43690 57231 44567 21845 21845 43690 43690 21845>,
			    <43705 56685 44989 19375 21845 43719 43644 21845>,
			    <43661 53397 45017 16202 21845 43967 43154 21845>,
			    <43664 54997 44899 65098 21845 43830 43474 21845>,
			    <43748 54486 44216 36529   934 43863 44589 32547>,
			    <43723 10893 44269 41741 37241 43161 45042 59325>,
			    <43554 10293 44273 43158 48652 43180 44257 46260>,
			    <43525 11992 44263 43781 47505 44024 44145 46777>,
			    <43625 12184 44271 43811 47167 43942 44476 45442>,
			    <43644 12149 44181 43994 47930 43610 44538 45898>,
			    <43607 11695 44189 44025 42152 43589 44399 48316>,
			    <43918  8875 44184 44009 41184 43611 41607 47348>,
			    <44006  8796 44167 43926 44392 43614 41686 42339>,
			    <43820  8423 44173 43933 44619 43606 41596 42620>,
			    <43783  8590 44174 43934 43384 43944 41904 41238>,
			    <43857  9733 44214 43909 43023 43942 41757 41002>,
			    <43255  9441 44219 43907 43840 43966 41151 41754>,
			    <43128  9680 44197 44000 43841 43958 41486 41853>,
			    <43505  9575 44198 43904 43823 43907 41635 41954>,
			    <45033 14987 44884 43584 43937 43925 41304 41694>,
			    <44318 15209 44891 43596 44016 44005 41511 41472>,
			    <41103 14401 44912 43632 43786 44004 44345 41581>,
			    <42556 16015 44909 43612 43044 44017 44136 41838>,
			    <42413 16304 44827 43614 43192 44031 44280 41860>,
			    <48082 15519 44854 43608 43831 44011 44425 41481>,
			    <47427 15625 44833 43600 43989 43921 44504 41512>,
			    <48368 13180 45015 43976 43084 43907 44172 41213>,
			    <45627 14061 45018 43792 43411 43960 44863 41377>,
			    <45480 13334 45003 43981 43174 43949 44635 41936>,
			    <47035  2646 45053 43977 43808 43946 44179 41551>,
			    <46376  2429 45028 44005 44011 43938 44301 41682>,
			    <35673  3175 45037 43928 43910 43961 41612 41618>,
			    <36558   822 45033 43940 44013 43914 44391 41608>,
			    <36042   357 44956 43947 43968 43907 44379 41652>,
			    <36282  1598 44953 43946 43997 43905 41650 41610>;
	};

	qcom,bp-d-table-7 {
		qcom,temperature = <50>;
		qcom,nrows = <35>;
		qcom,ncols = <8>;
		qcom,conv-factor = <10000 10000 10000 10000 10000 100000 100000 10000>;
		qcom,data = <43690 56644 44215 44923 45517 44721 43780 33281>,
			    <43705 54215 44217 44995 45229 43353 43239 35938>,
			    <43661 53325 44192 44611 45761 43265 43073 36390>,
			    <43664 55027 44202 44786 48130 43494 43308 35005>,
			    <43748 55061 44892 43285 48761 43125 44727 46380>,
			    <43723 54706 44871 43407 47189 43206 44548 46685>,
			    <43554 11045 44913 43172 42270 43826 44828 45810>,
			    <43525 10511 44900 44025 42945 43964 44091 49027>,
			    <43625 11817 44896 43904 42608 43938 44096 48847>,
			    <43644 12256 44908 43962 42529 43938 44434 47441>,
			    <43607 11279 44906 43585 42624 43938 44308 47570>,
			    <43918 11618 44822 43639 41272 43939 41604 47122>,
			    <44006  8733 44819 43633 41884 43940 41507 47848>,
			    <43820  9051 44830 43632 44613 43952 41890 41300>,
			    <43783  8297 44826 43633 43283 43957 41926 41067>,
			    <43857  9953 44803 43636 43263 43917 41186 41977>,
			    <43255 10054 44808 43636 43803 43931 41352 41476>,
			    <43128  9630 44811 43613 43827 43933 41154 41473>,
			    <43505  9520 44853 43615 44026 44002 41214 41718>,
			    <45033  9561 44857 43631 43599 43971 42425 44295>,
			    <44318 15141 44834 43642 43931 43816 41448 44383>,
			    <41103 14358 45011 43544 44009 43814 41645 44400>,
			    <42556 16050 44996 43551 43853 43825 44275 41694>,
			    <42413 16266 45044 43643 43787 43818 44419 41617>,
			    <48082 15509 45030 43621 43920 43995 41582 44398>,
			    <47427 15623 44949 43616 43916 43981 41593 44303>,
			    <48368 13130 44958 43957 43163 43924 44514 41900>,
			    <45627 14051 44941 43935 43219 43905 45054 41921>,
			    <45480 13328 44976 43909 43994 43918 44036 41702>,
			    <47035  2653 44967 43919 43966 43915 41590 44403>,
			    <46376  2405 44625 43943 43586 43907 41079 44503>,
			    <35673  3179 44615 43591 43594 43929 41402 44436>,
			    <36558   806 44661 43647 43590 44012 41164 44464>,
			    <36042   278 44641 43624 43943 44026 41903 44478>,
			    <36282  1578 44654 43542 43967 44025 41485 44467>;
	};
};
